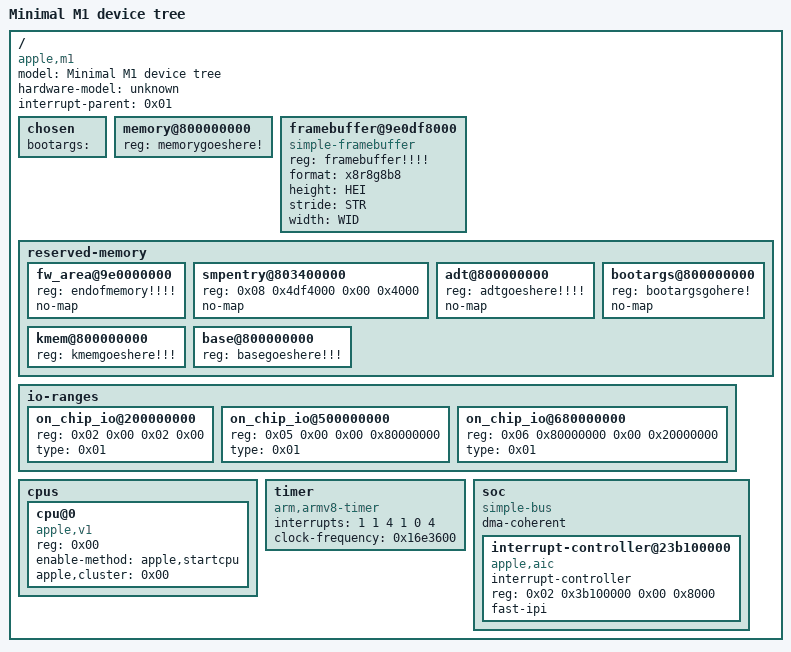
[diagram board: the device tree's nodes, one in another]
/dts-v1/;

/ {
	model = "Minimal M1 device tree";
	compatible = "apple,m1";
	hardware-model = "unknown";
	interrupt-parent = <0x01>;
	#address-cells = <0x02>;
	#size-cells = <0x02>;

	chosen {
		bootargs = "";
	};

	memory@800000000 {
		device_type = "memory";
		reg = "memorygoeshere!";
	};

	framebuffer@9e0df8000 {
		#address-cells = <0x02>;
		#size-cells = <0x02>;
		compatible = "simple-framebuffer";
		reg = "framebuffer!!!!";
		format = "x8r8g8b8";
		height = "HEI";
		stride = "STR";
		width = "WID";
		status = "okay";
	};

	reserved-memory {
		#address-cells = <0x02>;
		#size-cells = <0x02>;
		ranges;

		fw_area@9e0000000 {
		        reg = "endofmemory!!!!";
			no-map;
		};

		smpentry@803400000 {
			reg = <0x08 0x4df4000 0x00 0x4000>;
			no-map;
		};

		adt@800000000 {
			reg = "adtgoeshere!!!!";
			no-map;
		};

		bootargs@800000000 {
			reg = "bootargsgohere!";
			no-map;
		};

		kmem@800000000 {
			reg = "kmemgoeshere!!!";
		};

		base@800000000 {
			reg = "basegoeshere!!!";
		};
	};

	io-ranges {
		#address-cells = <0x02>;
		#size-cells = <0x02>;
		ranges;

		on_chip_io@200000000 {
			reg = <0x02 0x00 0x02 0x00>;
			type = <0x01>;
		};

		on_chip_io@500000000 {
			reg = <0x05 0x00 0x00 0x80000000>;
			type = <0x01>;
		};

		on_chip_io@680000000 {
			reg = <0x06 0x80000000 0x00 0x20000000>;
			type = <0x01>;
		};
	};

	cpus {
		#address-cells = <0x01>;
		#size-cells = <0x00>;

		cpu@0 {
			device_type = "cpu";
			compatible = "apple,v1";
			reg = <0x00>;
			enable-method = "apple,startcpu";
			apple,cluster = <0x00>;
		};
	};

	timer {
		compatible = "arm,armv8-timer";
		interrupts = <1 1 4 1 0 4>;
		clock-frequency = <0x16e3600>;
	};

	soc {
		compatible = "simple-bus";
		#address-cells = <0x02>;
		#size-cells = <0x02>;
		ranges;
		dma-coherent;

		interrupt-controller@23b100000 {
			compatible = "apple,aic";
			#interrupt-cells = <0x03>;
			interrupt-controller;
			reg = <0x02 0x3b100000 0x00 0x8000>;
			fast-ipi;
			phandle = <0x01>;
		};
	};
};
